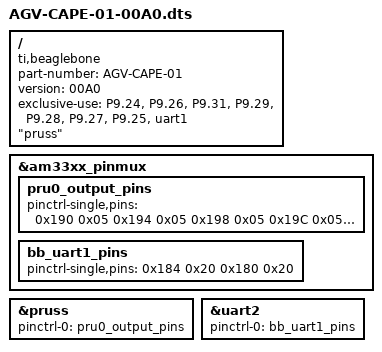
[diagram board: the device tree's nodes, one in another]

/dts-v1/;
/plugin/;

/ {
    compatible = "ti,beaglebone", "ti,beaglebone-black";

    /* identification */
    part-number = "AGV-CAPE-01";

  /* version */
    version = "00A0";



        /* state the resources this cape uses */
        exclusive-use =
                /* the pin header uses */
 /              "P9.24",        /* uart1_txd */
                "P9.26",        /* uart1_rxd */
//
//		"P9.21",	/* uart2_txd */
//		"P9.22",	/* uart2_rxd */
//
//		"P9.18",	/* i2c1_sda */
//		"P9.17",	/* i2c1_scl */
//
                "P9.31",        /* PRU PWM */
                "P9.29",        /* PRU PWM */
                "P9.28",        /* PRU PWM */
                "P9.27",        /* PRU PWM */
                "P9.25",        /* PRU PWM */
       /* the hardware ip uses */
//		"i2c1";
                "uart1";
//		"uart2";
 		"pruss"; 





    fragment@0 {
        target = <&am33xx_pinmux>;
        __overlay__ {
        		  pru0_output_pins: pru0_output_pins {
             		  	pinctrl-single,pins = <
					
					0x190 0x05  /* P9_31 to PRU output */
                    			0x194 0x05  /* P9_29 to PRU output */
					0x198 0x05  /* P9_30 to PRU output */
					0x19C 0x05  /* P9_28 to PRU output */
                    			0x1A4 0x05  /* P9_27 to PRU output */                   		
					0x1AC 0x05  /* P9_25 to PRU output */
					
                >;
            };

	 bb_uart1_pins: bb_uart1_pins {
            		 	pinctrl-single,pins = <
                                        0x184 0x20 /* P9.24 uart1_txd.uart1_txd MODE0 OUTPUT (TX) */
                                        0x180 0x20 /* P9.26 uart1_rxd.uart1_rxd MODE0 INPUT (RX) */
               >;
           };


	};
	};

	 		 

			
			

  

    fragment@1 {
        target = <&pruss>;
        __overlay__ {
			status = "okay";
			pinctrl-names = "default";
			pinctrl-0 = <&pru0_output_pins>;
		};
	};



fragment@2 {
 	target = <&uart2>;	/* really uart1 */
        __overlay__ {
                        status = "okay";
                        pinctrl-names = "default";
                        pinctrl-0 = <&bb_uart1_pins>;
                };
	};

};

